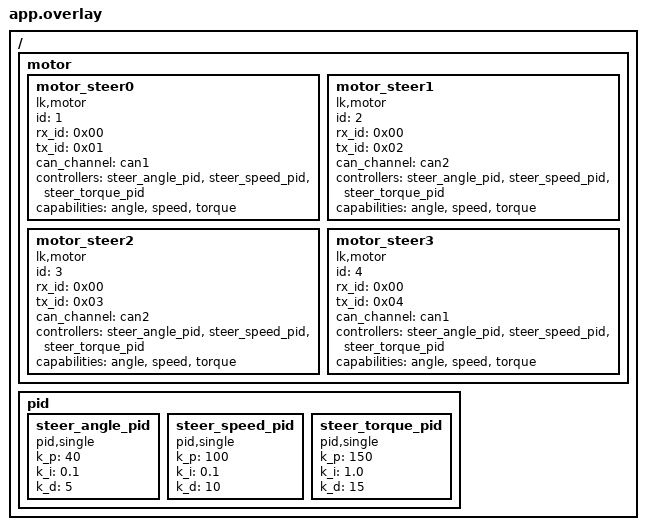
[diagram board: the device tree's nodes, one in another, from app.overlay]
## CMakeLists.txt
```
cmake_minimum_required(VERSION 3.20.0)

find_package(Zephyr REQUIRED HINTS $ENV{ZEPHYR_BASE})
project(lk_rom_zero)

target_sources(app PRIVATE src/main.c)
```

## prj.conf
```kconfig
CONFIG_MAIN_THREAD_PRIORITY=7
CONFIG_SYSTEM_WORKQUEUE_STACK_SIZE=2048

CONFIG_LOG=y
CONFIG_CBPRINTF_FP_SUPPORT=y

CONFIG_MOTOR=y
CONFIG_MOTOR_COMMON=y
CONFIG_MOTOR_LK=y
CONFIG_MOTOR_LOG_LEVEL=4
CONFIG_MOTOR_INIT_PRIORITY=90

CONFIG_CAN=y
CONFIG_CAN_INIT_PRIORITY=80

CONFIG_PID=y
```

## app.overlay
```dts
/ {
	motor {
		motor_steer0: motor_steer0 {
			compatible = "lk,motor";
			id = <1>;
			rx_id = <0x00>;
			tx_id = <0x01>;
			status = "okay";
			can_channel = <&can1>;
			controllers = <&steer_angle_pid &steer_speed_pid &steer_torque_pid>;
			capabilities = "angle", "speed", "torque";
		};

		motor_steer1: motor_steer1 {
			compatible = "lk,motor";
			id = <2>;
			rx_id = <0x00>;
			tx_id = <0x02>;
			status = "okay";
			can_channel = <&can2>;
			controllers = <&steer_angle_pid &steer_speed_pid &steer_torque_pid>;
			capabilities = "angle", "speed", "torque";
		};

		motor_steer2: motor_steer2 {
			compatible = "lk,motor";
			id = <3>;
			rx_id = <0x00>;
			tx_id = <0x03>;
			status = "okay";
			can_channel = <&can2>;
			controllers = <&steer_angle_pid &steer_speed_pid &steer_torque_pid>;
			capabilities = "angle", "speed", "torque";
		};

		motor_steer3: motor_steer3 {
			compatible = "lk,motor";
			id = <4>;
			rx_id = <0x00>;
			tx_id = <0x04>;
			status = "okay";
			can_channel = <&can1>;
			controllers = <&steer_angle_pid &steer_speed_pid &steer_torque_pid>;
			capabilities = "angle", "speed", "torque";
		};
	};

	pid {
		steer_angle_pid: steer_angle_pid {
			#controller-cells = <0>;
			compatible = "pid,single";
			k_p = "40";
			k_i = "0.1";
			k_d = "5";
		};

		steer_speed_pid: steer_speed_pid {
			#controller-cells = <0>;
			compatible = "pid,single";
			k_p = "100";
			k_i = "0.1";
			k_d = "10";
		};

		steer_torque_pid: steer_torque_pid {
			#controller-cells = <0>;
			compatible = "pid,single";
			k_p = "150";
			k_i = "1.0";
			k_d = "15";
		};
	};
};
```

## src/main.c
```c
#include <errno.h>

#include <zephyr/device.h>
#include <zephyr/drivers/motor.h>
#include <zephyr/kernel.h>
#include <zephyr/logging/log.h>

LOG_MODULE_REGISTER(lk_rom_zero, LOG_LEVEL_INF);

#define LK_ZERO_RETRIES 3
#define LK_ZERO_GAP_MS  150

static const struct device *const lk_motors[] = {
	DEVICE_DT_GET(DT_NODELABEL(motor_steer0)),
	DEVICE_DT_GET(DT_NODELABEL(motor_steer1)),
	DEVICE_DT_GET(DT_NODELABEL(motor_steer2)),
	DEVICE_DT_GET(DT_NODELABEL(motor_steer3)),
};

static int check_motors_ready(void)
{
	for (size_t i = 0; i < ARRAY_SIZE(lk_motors); i++) {
		if (!device_is_ready(lk_motors[i])) {
			LOG_ERR("%s not ready", lk_motors[i]->name);
			return -ENODEV;
		}
	}

	return 0;
}

int main(void)
{
	int ret = check_motors_ready();

	if (ret < 0) {
		return ret;
	}

	LOG_INF("LK ROM zero writer started");
	k_msleep(500);

	for (int retry = 0; retry < LK_ZERO_RETRIES; retry++) {
		for (size_t i = 0; i < ARRAY_SIZE(lk_motors); i++) {
			LOG_INF("SET_ZERO ROM: %s", lk_motors[i]->name);
			motor_control(lk_motors[i], SET_ZERO);
			k_msleep(LK_ZERO_GAP_MS);
		}
	}

	k_msleep(300);

	for (size_t i = 0; i < ARRAY_SIZE(lk_motors); i++) {
		motor_control(lk_motors[i], DISABLE_MOTOR);
	}

	LOG_INF("LK ROM zero commands sent. Power-cycle motors to use the stored zero.");

	while (1) {
		k_sleep(K_SECONDS(1));
	}

	return 0;
}
```
